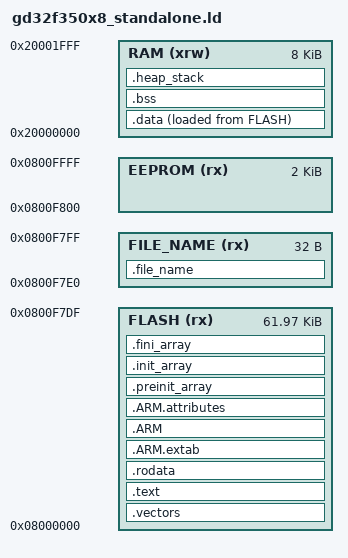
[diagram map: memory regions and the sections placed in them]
/* GD32F350x8 direct-SWD layout: application starts at the MCU reset address. */

MEMORY
{
  FLASH     (rx)  : ORIGIN = 0x08000000, LENGTH = 0xF7E0
  EEPROM    (rx)  : ORIGIN = 0x0800F800, LENGTH = 2K
  FILE_NAME (rx)  : ORIGIN = ORIGIN(EEPROM) - 32, LENGTH = 32
  RAM       (xrw) : ORIGIN = 0x20000000, LENGTH = 8K
}

ENTRY(Reset_Handler)

SECTIONS
{
  __stack_size = DEFINED(__stack_size) ? __stack_size : 2K;
  __heap_size = DEFINED(__heap_size) ? __heap_size : 1K;

  .vectors :
  {
    . = ALIGN(4);
    KEEP(*(.vectors))
    . = ALIGN(4);
    __Vectors_End = .;
    __Vectors_Size = __Vectors_End - __gVectors;
  } >FLASH

  .text :
  {
    . = ALIGN(4);
    *(.text)
    *(.text*)
    *(.glue_7)
    *(.glue_7t)
    *(.eh_frame)
    KEEP (*(.init))
    KEEP (*(.fini))
    . = ALIGN(4);
    _etext = .;
  } >FLASH

  .rodata :
  {
    . = ALIGN(4);
    *(.rodata)
    *(.rodata*)
    . = ALIGN(4);
  } >FLASH

  .ARM.extab :
  {
    *(.ARM.extab* .gnu.linkonce.armextab.*)
  } >FLASH

  .ARM :
  {
    __exidx_start = .;
    *(.ARM.exidx*)
    __exidx_end = .;
  } >FLASH

  .ARM.attributes :
  {
    *(.ARM.attributes)
  } >FLASH

  .preinit_array :
  {
    PROVIDE_HIDDEN (__preinit_array_start = .);
    KEEP (*(.preinit_array*))
    PROVIDE_HIDDEN (__preinit_array_end = .);
  } >FLASH

  .init_array :
  {
    PROVIDE_HIDDEN (__init_array_start = .);
    KEEP (*(SORT(.init_array.*)))
    KEEP (*(.init_array*))
    PROVIDE_HIDDEN (__init_array_end = .);
  } >FLASH

  .fini_array :
  {
    PROVIDE_HIDDEN (__fini_array_start = .);
    KEEP (*(SORT(.fini_array.*)))
    KEEP (*(.fini_array*))
    PROVIDE_HIDDEN (__fini_array_end = .);
  } >FLASH

  .file_name :
  {
    . = ALIGN(4);
    KEEP (*(.file_name))
    . = ALIGN(4);
  } >FILE_NAME

  _sidata = LOADADDR(.data);
  .data :
  {
    . = ALIGN(4);
    _sdata = .;
    *(.data)
    *(.data*)
    . = ALIGN(4);
    _edata = .;
  } > RAM AT> FLASH

  . = ALIGN(4);
  .bss :
  {
    . = ALIGN(4);
    _sbss = .;
    __bss_start__ = _sbss;
    *(.bss)
    *(.bss*)
    *(COMMON)
    . = ALIGN(4);
    _ebss = .;
    __bss_end__ = _ebss;
  } > RAM

  .heap_stack :
  {
    . = ALIGN(8);
    PROVIDE ( end = _ebss );
    PROVIDE ( _end = _ebss );
    . = . + __heap_size;
    PROVIDE ( _heap_end = . );
    . = . + __stack_size;
    PROVIDE ( _sp = . );
    . = ALIGN(8);
  } > RAM
}

GROUP(libgcc.a libc.a libm.a libnosys.a)
